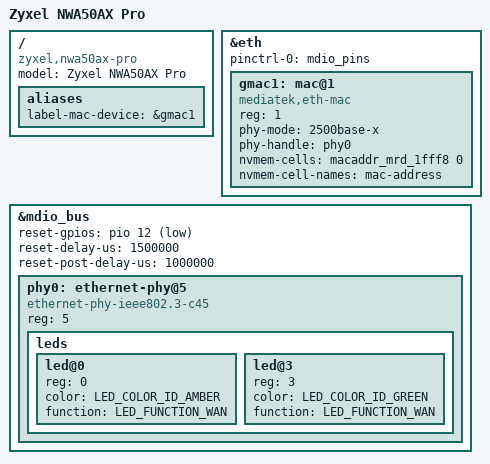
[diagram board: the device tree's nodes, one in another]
// SPDX-License-Identifier: (GPL-2.0-or-later OR MIT)
/dts-v1/;

#include "mt7981b-zyxel-common.dtsi"

/ {
	model = "Zyxel NWA50AX Pro";
	compatible = "zyxel,nwa50ax-pro", "mediatek,mt7981";

	aliases {
		label-mac-device = &gmac1;
	};
};

&eth {
	pinctrl-names = "default";
	pinctrl-0 = <&mdio_pins>;

	status = "okay";

	gmac1: mac@1 {
		compatible = "mediatek,eth-mac";
		reg = <1>;
		phy-mode = "2500base-x";
		phy-handle = <&phy0>;

		nvmem-cells = <&macaddr_mrd_1fff8 0>;
		nvmem-cell-names = "mac-address";
	};
};

&mdio_bus {
	reset-gpios = <&pio 12 GPIO_ACTIVE_LOW>;
	reset-delay-us = <1500000>;
	reset-post-delay-us = <1000000>;

	phy0: ethernet-phy@5 {
		reg = <5>;
		compatible = "ethernet-phy-ieee802.3-c45";

		leds {
			#address-cells = <1>;
			#size-cells = <0>;

			led@0 {
				reg = <0>;
				color = <LED_COLOR_ID_AMBER>;
				function = LED_FUNCTION_WAN;
			};

			led@3 {
				reg = <3>;
				color = <LED_COLOR_ID_GREEN>;
				function = LED_FUNCTION_WAN;
			};
		};
	};
};
